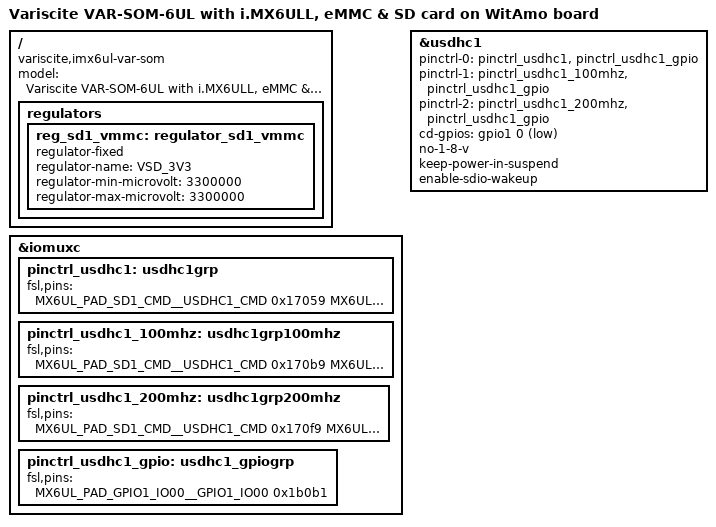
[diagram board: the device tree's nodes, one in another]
/*
 * Copyright (C) NKE
 *
 */

 /dts-v1/;

 #include "imx6ull-wiatmo.dtsi"

/{
	model = "Variscite VAR-SOM-6UL with i.MX6ULL, eMMC & SD card on WitAmo board";
	compatible = "variscite,imx6ul-var-som", "fsl,imx6ull";

	regulators {
		reg_sd1_vmmc: regulator_sd1_vmmc {
			compatible = "regulator-fixed";
			regulator-name = "VSD_3V3";
			regulator-min-microvolt = <3300000>;
			regulator-max-microvolt = <3300000>;
		};
	};

};


&iomuxc {
	pinctrl_usdhc1: usdhc1grp {
		fsl,pins = <
			MX6UL_PAD_SD1_CMD__USDHC1_CMD		0x17059
			MX6UL_PAD_SD1_CLK__USDHC1_CLK		0x17059
			MX6UL_PAD_SD1_DATA0__USDHC1_DATA0	0x17059
			MX6UL_PAD_SD1_DATA1__USDHC1_DATA1	0x17059
			MX6UL_PAD_SD1_DATA2__USDHC1_DATA2	0x17059
			MX6UL_PAD_SD1_DATA3__USDHC1_DATA3	0x17059
		>;
	};

	pinctrl_usdhc1_100mhz: usdhc1grp100mhz {
		fsl,pins = <
			MX6UL_PAD_SD1_CMD__USDHC1_CMD		0x170b9
			MX6UL_PAD_SD1_CLK__USDHC1_CLK		0x100b9
			MX6UL_PAD_SD1_DATA0__USDHC1_DATA0	0x170b9
			MX6UL_PAD_SD1_DATA1__USDHC1_DATA1	0x170b9
			MX6UL_PAD_SD1_DATA2__USDHC1_DATA2	0x170b9
			MX6UL_PAD_SD1_DATA3__USDHC1_DATA3	0x170b9
		>;
	};

	pinctrl_usdhc1_200mhz: usdhc1grp200mhz {
		fsl,pins = <
			MX6UL_PAD_SD1_CMD__USDHC1_CMD		0x170f9
			MX6UL_PAD_SD1_CLK__USDHC1_CLK		0x100f9
			MX6UL_PAD_SD1_DATA0__USDHC1_DATA0	0x170f9
			MX6UL_PAD_SD1_DATA1__USDHC1_DATA1	0x170f9
			MX6UL_PAD_SD1_DATA2__USDHC1_DATA2	0x170f9
			MX6UL_PAD_SD1_DATA3__USDHC1_DATA3	0x170f9
		>;
	};

	pinctrl_usdhc1_gpio: usdhc1_gpiogrp {
		fsl,pins = <
			MX6UL_PAD_GPIO1_IO00__GPIO1_IO00	0x1b0b1 /* CD */
		>;
	};
};

&usdhc1 {
	pinctrl-names = "default", "state_100mhz", "state_200mhz";
	pinctrl-0 = <&pinctrl_usdhc1>, <&pinctrl_usdhc1_gpio>;
	pinctrl-1 = <&pinctrl_usdhc1_100mhz>, <&pinctrl_usdhc1_gpio>;
	pinctrl-2 = <&pinctrl_usdhc1_200mhz>, <&pinctrl_usdhc1_gpio>;
	cd-gpios = <&gpio1 0 GPIO_ACTIVE_LOW>;
	no-1-8-v;
	keep-power-in-suspend;
	enable-sdio-wakeup;
	status = "okay";
};
